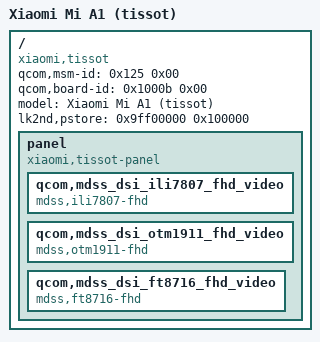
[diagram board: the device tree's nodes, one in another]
// SPDX-License-Identifier: GPL-2.0-only

/dts-v1/;

/include/ "msm8953.dtsi"

/ {
	// This is used by the bootloader to find the correct DTB 
	qcom,msm-id = <0x125 0x00>;
	qcom,board-id= <0x1000b 0x00>;

	model = "Xiaomi Mi A1 (tissot)";
	compatible = "xiaomi,tissot", "qcom,msm8953", "lk2nd,device";
	lk2nd,pstore = <0x9ff00000 0x100000>;

	panel {
		compatible = "xiaomi,tissot-panel";

		qcom,mdss_dsi_ili7807_fhd_video {
			compatible = "mdss,ili7807-fhd";
		};
		qcom,mdss_dsi_otm1911_fhd_video {
			compatible = "mdss,otm1911-fhd";
		};
		qcom,mdss_dsi_ft8716_fhd_video {
			compatible = "mdss,ft8716-fhd";
		};
	};
};
